# ESP32-S2 register map
Vendor: ESPRESSIF SYSTEMS (SHANGHAI) CO., LTD.; Series: ESP32 S-Series; File version: 20
CPU: Xtensa LX7 r0p0, little endian, no MPU, no FPU, 0 interrupt priority bits
Address unit: 32 bits
Registers are 32-bit, read-write, reset 0x0 unless marked. A register's access mark holds for its fields unless they carry their own. Offsets are from the block's base; [hi:lo] are bit positions; {n}, {i} and the like mark numbered series; 'fields as' and 'values as' point back to an identical list.

## RTC_IO — Low-power Input/Output
Base 0x3F408400
0x00 RTC_GPIO_OUT — RTC GPIO output register
  [31:10] GPIO_OUT_DATA — GPIO0 ~ 21 output register. Bit10 corresponds to GPIO0, bit11 corresponds to GPIO1, etc.
0x04 RTC_GPIO_OUT_W1TS wo — RTC GPIO output bit set register
  [31:10] GPIO_OUT_DATA_W1TS — GPIO0 ~ 21 output set register. If the value 1 is written to a bit here, the corresponding bit in RTCIO_RTC_GPIO_OUT_REG will be set to 1. Recommended operation: use this register to set RTCIO_RTC_GPIO_OUT_REG.
0x08 RTC_GPIO_OUT_W1TC wo — RTC GPIO output bit clear register
  [31:10] GPIO_OUT_DATA_W1TC — GPIO0 ~ 21 output clear register. If the value 1 is written to a bit here, the corresponding bit in RTCIO_RTC_GPIO_OUT_REG will be cleared. Recommended operation: use this register to clear RTCIO_RTC_GPIO_OUT_REG.
0x0C RTC_GPIO_ENABLE — RTC GPIO output enable register
  [31:10] REG_RTCIO_REG_GPIO_ENABLE — GPIO0 ~ 21 output enable. Bit10 corresponds to GPIO0, bit11 corresponds to GPIO1, etc. If the bit is set to 1, it means this GPIO pad is output.
0x10 RTC_GPIO_ENABLE_W1TS wo — RTC GPIO output enable bit set register
  [31:10] REG_RTCIO_REG_GPIO_ENABLE_W1TS — GPIO0 ~ 21 output enable set register. If the value 1 is written to a bit here, the corresponding bit in RTCIO_RTC_GPIO_ENABLE_REG will be set to 1. Recommended operation: use this register to set RTCIO_RTC_GPIO_ENABLE_REG.
0x14 RTC_GPIO_ENABLE_W1TC wo — RTC GPIO output enable bit clear register
  [31:10] REG_RTCIO_REG_GPIO_ENABLE_W1TC — GPIO0 ~ 21 output enable clear register. If the value 1 is written to a bit here, the corresponding bit in RTCIO_RTC_GPIO_ENABLE_REG will be cleared. Recommended operation: use this register to clear RTCIO_RTC_GPIO_ENABLE_REG.
0x18 RTC_GPIO_STATUS — RTC GPIO interrupt status register
  [31:10] GPIO_STATUS_INT — GPIO0 ~ 21 interrupt status register. Bit10 corresponds to GPIO0, bit11 corresponds to GPIO1, etc. This register should be used together with RTCIO_RTC_GPIO_PINn_INT_TYPE in RTCIO_RTC_GPIO_PINn_REG. 0: no interrupt; 1: corresponding interrupt.
0x1C RTC_GPIO_STATUS_W1TS wo — RTC GPIO interrupt status bit set register
  [31:10] GPIO_STATUS_INT_W1TS — GPIO0 ~ 21 interrupt set register. If the value 1 is written to a bit here, the corresponding bit in RTCIO_GPIO_STATUS_INT will be set to 1. Recommended operation: use this register to set RTCIO_GPIO_STATUS_INT.
0x20 RTC_GPIO_STATUS_W1TC wo — RTC GPIO interrupt status bit clear register
  [31:10] GPIO_STATUS_INT_W1TC — GPIO0 ~ 21 interrupt clear register. If the value 1 is written to a bit here, the corresponding bit in RTCIO_GPIO_STATUS_INT will be cleared. Recommended operation: use this register to clear RTCIO_GPIO_STATUS_INT.
0x24 RTC_GPIO_IN ro — RTC GPIO input register
  [31:10] GPIO_IN_NEXT — GPIO0 ~ 21 input value. Bit10 corresponds to GPIO0, bit11 corresponds to GPIO1, etc. Each bit represents a pad input value, 1 for high level, and 0 for low level.
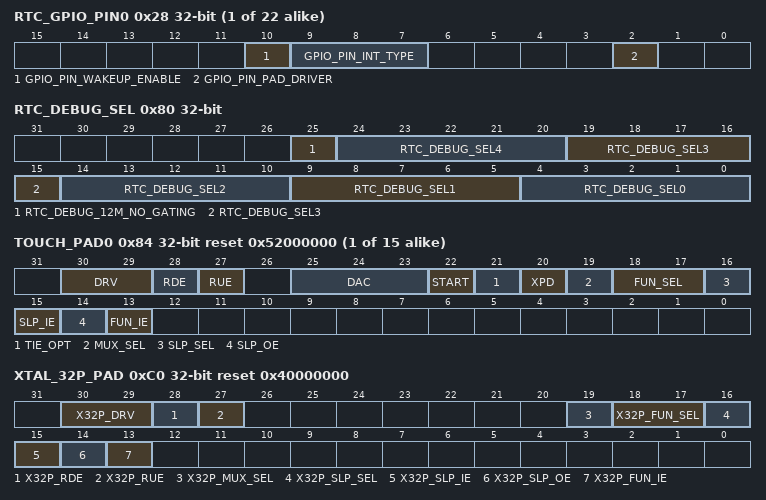
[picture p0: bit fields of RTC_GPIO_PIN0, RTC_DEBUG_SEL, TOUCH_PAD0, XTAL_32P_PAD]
{0x28+4i} RTC_GPIO_PIN{i} (i=0..21) — RTC configuration for pin {i}
  [10] GPIO_PIN_WAKEUP_ENABLE — GPIO wake-up enable. This will only wake up ESP32-S2 from Light-sleep.
  [9:7] GPIO_PIN_INT_TYPE — GPIO interrupt type selection. 0: GPIO interrupt disabled. 1: rising edge trigger. 2: falling edge trigger. 3: any edge trigger. 4: low level trigger. 5: high level trigger.
  [2] GPIO_PIN_PAD_DRIVER — Pad driver selection. 0: normal output. 1: open drain.
0x80 RTC_DEBUG_SEL — RTC debug select register
  [25] RTC_DEBUG_12M_NO_GATING, [5n+4:5n] RTC_DEBUG_SEL{n} (n=0..4)
{0x84+4i} TOUCH_PAD{i} (i=0..14) reset 0x52000000 — Touch pad {i} configuration register
  [30:29] DRV — Select the drive strength of the pad. 0: ~5 mA. 1: ~10 mA. 2: ~20 mA. 3: ~40 mA.
  [28] RDE — Pull-up enable of the pad. 1: internal pull-up enabled. 0: internal pull-up disabled.
  [27] RUE — Pull-down enable of the pad. 1: internal pull-down enabled. 0: internal pull-down disabled.
  [25:23] DAC — Touch sensor slope control. 3-bit for each touch pad, defaults to 0x4.
  [22] START — Start touch sensor.
  [21] TIE_OPT — The tie option of touch sensor. 0: tie low. 1: tie high.
  [20] XPD — Touch sensor power on.
  [19] MUX_SEL — Connect the RTC pad input to digital pad input. 0 is available.
  [18:17] FUN_SEL — Function selection.
  [16] SLP_SEL — 0: no sleep mode. 1: enable sleep mode.
  [15] SLP_IE — Input enable in sleep mode.
  [14] SLP_OE — Output enable in sleep mode.
  [13] FUN_IE — Input enable in normal execution.
0xC0 XTAL_32P_PAD reset 0x40000000 — 32KHz crystal P-pad configuration register
  [30:29] X32P_DRV — Select the drive strength of the pad. 0: ~5 mA. 1: ~10 mA. 2: ~20 mA. 3: ~40 mA.
  [28] X32P_RDE — Pull-up enable of the pad. 1: internal pull-up enabled. 0: internal pull-up disabled.
  [27] X32P_RUE — Pull-down enable of the pad. 1: internal pull-down enabled. 0: internal pull-down disabled.
  [19] X32P_MUX_SEL — 1: use RTC GPIO. 0: use digital GPIO.
  [18:17] X32P_FUN_SEL — Function selection.
  [16] X32P_SLP_SEL — 1: enable sleep mode. 0: no sleep mode.
  [15] X32P_SLP_IE — input enable in sleep mode.
  [14] X32P_SLP_OE — output enable in sleep mode.
  [13] X32P_FUN_IE — Input enable in normal execution.
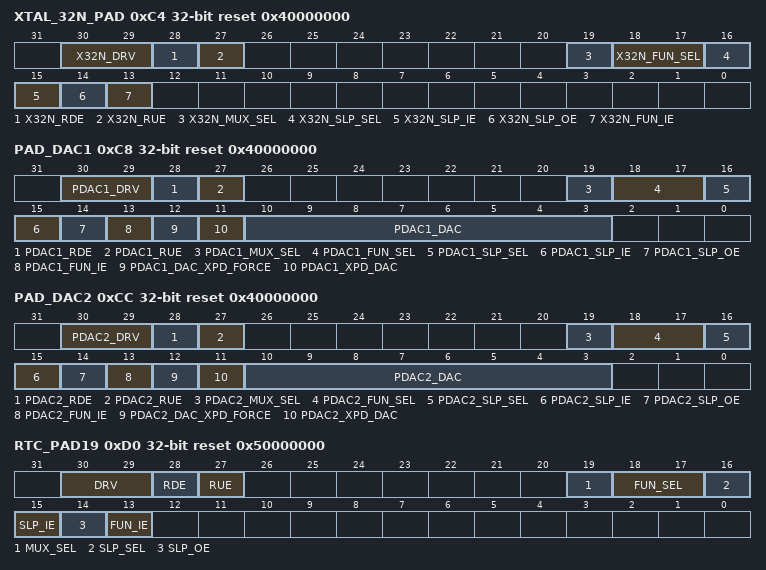
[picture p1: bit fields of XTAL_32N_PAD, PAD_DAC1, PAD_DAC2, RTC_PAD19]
0xC4 XTAL_32N_PAD reset 0x40000000 — 32KHz crystal N-pad configuration register
  [30:29] X32N_DRV — Select the drive strength of the pad. 0: ~5 mA. 1: ~10 mA. 2: ~20 mA. 3: ~40 mA.
  [28] X32N_RDE — Pull-up enable of the pad. 1: internal pull-up enabled. 0: internal pull-up disabled.
  [27] X32N_RUE — Pull-down enable of the pad. 1: internal pull-down enabled. 0: internal pull-down disabled.
  [19] X32N_MUX_SEL — 1: use RTC GPIO. 0: use digital GPIO.
  [18:17] X32N_FUN_SEL — Function selection.
  [16] X32N_SLP_SEL — 1: enable sleep mode. 0: no sleep mode.
  [15] X32N_SLP_IE — Input enable in sleep mode.
  [14] X32N_SLP_OE — Output enable in sleep mode.
  [13] X32N_FUN_IE — Input enable in normal execution.
0xC8 PAD_DAC1 reset 0x40000000 — DAC1 configuration register
  [30:29] PDAC1_DRV — Select the drive strength of the pad. 0: ~5 mA. 1: ~10 mA. 2: ~20 mA. 3: ~40 mA.
  [28] PDAC1_RDE — Pull-up enable of the pad. 1: internal pull-up enabled. 0: internal pull-up disabled.
  [27] PDAC1_RUE — Pull-down enable of the pad. 1: internal pull-down enabled. 0: internal pull-down disabled.
  [19] PDAC1_MUX_SEL — 1: use RTC GPIO. 0: use digital GPIO
  [18:17] PDAC1_FUN_SEL — DAC_1 function selection.
  [16] PDAC1_SLP_SEL — 1: enable sleep mode. 0: no sleep mode
  [15] PDAC1_SLP_IE — Input enable in sleep mode
  [14] PDAC1_SLP_OE — Output enable in sleep mode
  [13] PDAC1_FUN_IE — Input enable in normal execution.
  [12] PDAC1_DAC_XPD_FORCE — 1: use RTCIO_PDAC1_XPD_DAC to control DAC_1 output. 0: use SAR ADC FSM to control DAC_1 output.
  [11] PDAC1_XPD_DAC — When RTCIO_PDAC1_DAC_XPD_FORCE is set to 1, 1: enable DAC_1 output. 0: disable DAC_1 output.
  [10:3] PDAC1_DAC — Configure DAC_1 output when RTCIO_PDAC1_DAC_XPD_FORCE is set to 1.
0xCC PAD_DAC2 reset 0x40000000 — DAC2 configuration register
  [30:29] PDAC2_DRV — Select the drive strength of the pad. 0: ~5 mA: 1: ~10 mA. 2: ~20 mA. 3: ~40 mA.
  [28] PDAC2_RDE — Pull-up enable of the pad. 1: internal pull-up enabled. 0: internal pull-up disabled.
  [27] PDAC2_RUE — Pull-down enable of the pad. 1: internal pull-down enabled. 0: internal pull-down disabled.
  [19] PDAC2_MUX_SEL — 1: use RTC GPIO. 0: use digital GPIO.
  [18:17] PDAC2_FUN_SEL — DAC_2 function selection.
  [16] PDAC2_SLP_SEL — 1: enable sleep mode. 0: no sleep mode.
  [15] PDAC2_SLP_IE — Input enable in sleep mode.
  [14] PDAC2_SLP_OE — Output enable in sleep mode.
  [13] PDAC2_FUN_IE — Input enable in normal execution.
  [12] PDAC2_DAC_XPD_FORCE — 1: use RTCIO_PDAC2_XPD_DAC to control DAC_2 output. 0: use SAR ADC FSM to control DAC_2 output.
  [11] PDAC2_XPD_DAC — When RTCIO_PDAC2_DAC_XPD_FORCE is set to 1, 1: enable DAC_2 output. 0: disable DAC_2 output.
  [10:3] PDAC2_DAC — Configure DAC_2 output when RTCIO_PDAC2_DAC_XPD_FORCE is set to 1.
0xD0 RTC_PAD19 reset 0x50000000 — Touch pad 19 configuration register
  [30:29] DRV — Select the drive strength of the pad. 0: ~5 mA. 1: ~10 mA. 2: ~20 mA. 3: ~40 mA.
  [28] RDE — Pull-up enable of the pad. 1: internal pull-up enabled. 0: internal pull-up disabled.
  [27] RUE — Pull-down enable of the pad. 1: internal pull-down enabled. 0: internal pull-down disabled.
  [19] MUX_SEL — 1: use RTC GPIO. 0: use digital GPIO.
  [18:17] FUN_SEL — Function selection.
  [16] SLP_SEL — 1: enable sleep mode. 0: no sleep mode
  [15] SLP_IE — Input enable in sleep mode.
  [14] SLP_OE — Output enable in sleep mode.
  [13] FUN_IE — Input enable in normal execution.
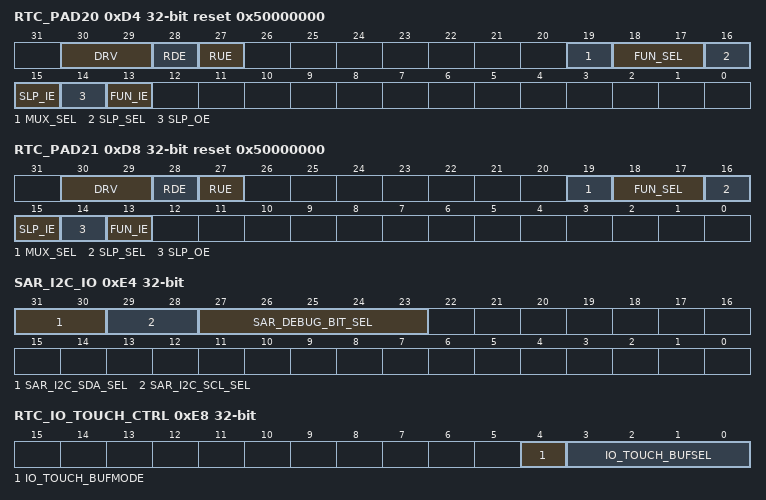
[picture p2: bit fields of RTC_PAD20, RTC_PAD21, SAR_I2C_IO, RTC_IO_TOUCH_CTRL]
0xD4 RTC_PAD20 reset 0x50000000 — Touch pad 20 configuration register
  [30:29] DRV — Select the drive strength of the pad. 0: ~5 mA. 1: ~10 mA. 2: ~20 mA. 3: ~40 mA.
  [28] RDE — Pull-up enable of the pad. 1: internal pull-up enabled. 0: internal pull-up disabled.
  [27] RUE — Pull-down enable of the pad. 1: internal pull-down enabled. 0: internal pull-down disabled.
  [19] MUX_SEL — 1: use RTC GPIO. 0: use digital GPIO.
  [18:17] FUN_SEL — Function selection.
  [16] SLP_SEL — 1: enable sleep mode. 0: no sleep mode.
  [15] SLP_IE — Input enable in sleep mode.
  [14] SLP_OE — Output enable in sleep mode.
  [13] FUN_IE — Input enable in normal execution.
0xD8 RTC_PAD21 reset 0x50000000 — Touch pad 21 configuration register
  fields as RTC_PAD20
0xDC EXT_WAKEUP0 — External wake up configuration register
  [31:27] SEL — GPIO[0-17] can be used to wake up the chip when the chip is in the sleep mode. This register prompts the pad source to wake up the chip when the latter is indeep/light sleep mode. 0: select GPIO0; 1: select GPIO2, etc
0xE0 XTL_EXT_CTR — Crystal power down enable GPIO source
  [31:27] SEL — Select the external crystal power down enable source to get into sleep mode. 0: select GPIO0. 1: select GPIO1, etc. The input value on this pin XOR RTC_CNTL_EXT_XTL_CONF_REG[30] is the crystal power down enable signal.
0xE4 SAR_I2C_IO — RTC I2C pad selection
  [31:30] SAR_I2C_SDA_SEL — Selects a pad the RTC I2C SDA signal connects to. 0: use TOUCH PAD1. 1: use TOUCH PAD3.
  [29:28] SAR_I2C_SCL_SEL — Selects a pad the RTC I2C SCL signal connects to. 0: use TOUCH PAD0. 1: use TOUCH PAD2.
  [27:23] SAR_DEBUG_BIT_SEL
0xE8 RTC_IO_TOUCH_CTRL — Touch control register
  [4] IO_TOUCH_BUFMODE, [3:0] IO_TOUCH_BUFSEL
0x1FC RTC_IO_DATE reset 0x1903170 — Version control register
  [27:0] IO_DATE
